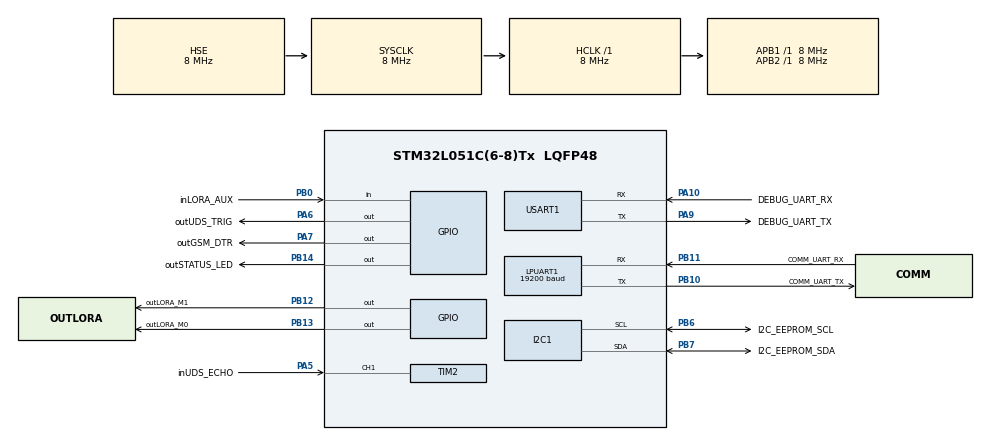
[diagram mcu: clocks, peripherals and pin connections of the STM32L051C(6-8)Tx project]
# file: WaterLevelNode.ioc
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ADC.ClockPrescaler=ADC_CLOCK_SYNC_PCLK_DIV4
ADC.SamplingTime=ADC_SAMPLETIME_7CYCLES_5
I2C1.I2C_Fall_Time=10
I2C1.I2C_Rise_Time=10
I2C1.Timing=0x2000090E
LPUART1.BaudRate=19200
LPUART1.WordLength=UART_WORDLENGTH_8B
Mcu.Family=STM32L0
Mcu.Name=STM32L051C(6-8)Tx
Mcu.Package=LQFP48
NVIC.LPUART1_IRQn=true\:0\:0\:false\:false\:true\:true\:true\:true
NVIC.RTC_IRQn=true\:0\:0\:false\:false\:true\:true\:true\:true
NVIC.TIM2_IRQn=true\:0\:0\:false\:false\:true\:true\:true\:true
NVIC.USART1_IRQn=true\:0\:0\:false\:false\:true\:true\:true\:true
PA10.GPIO_Label=DEBUG_UART_RX
PA10.Mode=Asynchronous
PA10.Signal=USART1_RX
PA13.Mode=Serial_Wire
PA13.Signal=SYS_SWDIO
PA14.Mode=Serial_Wire
PA14.Signal=SYS_SWCLK
PA5.GPIO_Label=inUDS_ECHO
PA5.Signal=S_TIM2_CH1
PA6.GPIO_Label=outUDS_TRIG
PA6.Signal=GPIO_Output
PA7.GPIO_Label=outGSM_DTR
PA7.PinState=GPIO_PIN_RESET
PA7.Signal=GPIO_Output
PA9.GPIO_Label=DEBUG_UART_TX
PA9.Mode=Asynchronous
PA9.Signal=USART1_TX
PB0.GPIO_Label=inLORA_AUX
PB0.Signal=GPIO_Input
PB10.GPIO_Label=COMM_UART_TX
PB10.GPIO_PuPd=GPIO_NOPULL
PB10.Mode=Asynchronous
PB10.Signal=LPUART1_TX
PB11.GPIO_Label=COMM_UART_RX
PB11.GPIO_PuPd=GPIO_NOPULL
PB11.Mode=Asynchronous
PB11.Signal=LPUART1_RX
PB12.GPIO_Label=outLORA_M1
PB12.Signal=GPIO_Output
PB13.GPIO_Label=outLORA_M0
PB13.Signal=GPIO_Output
PB14.GPIO_Label=outSTATUS_LED
PB14.Signal=GPIO_Output
PB6.GPIO_Label=I2C_EEPROM_SCL
PB6.GPIO_Pu=GPIO_PULLUP
PB6.Mode=I2C
PB6.Signal=I2C1_SCL
PB7.GPIO_Label=I2C_EEPROM_SDA
PB7.GPIO_Pu=GPIO_PULLUP
PB7.Mode=I2C
PB7.Signal=I2C1_SDA
PC14-OSC32_IN.Mode=LSE-External-Oscillator
PC14-OSC32_IN.Signal=RCC_OSC32_IN
PC15-OSC32_OUT.Mode=LSE-External-Oscillator
PC15-OSC32_OUT.Signal=RCC_OSC32_OUT
PH0-OSC_IN.Mode=HSE-External-Oscillator
PH0-OSC_IN.Signal=RCC_OSC_IN
PH1-OSC_OUT.Mode=HSE-External-Oscillator
PH1-OSC_OUT.Signal=RCC_OSC_OUT
ProjectManager.HeapSize=0x200
ProjectManager.StackSize=0x400
ProjectManager.TargetToolchain=CMake
RCC.AHBFreq_Value=8000000
RCC.APB1Freq_Value=8000000
RCC.APB1TimFreq_Value=8000000
RCC.APB2Freq_Value=8000000
RCC.APB2TimFreq_Value=8000000
RCC.HCLKFreq_Value=8000000
RCC.HSE_VALUE=8000000
RCC.HSI16_VALUE=16000000
RCC.HSI_VALUE=16000000
RCC.MSI_VALUE=2097000
RCC.PLLDIV=RCC_PLLDIV_3
RCC.PLLSourceVirtual=RCC_PLLSOURCE_HSE
RCC.RTCClockSelection=RCC_RTCCLKSOURCE_LSE
RCC.RTCClockSelectionVirtual=RCC_RTCCLKSOURCE_LSE
RCC.SYSCLKFreq_VALUE=8000000
RCC.SYSCLKSource=RCC_SYSCLKSOURCE_HSE
RCC.VCOOutputFreq_Value=24000000
RTC.WakeUpClock-WakeUp=RTC_WAKEUPCLOCK_CK_SPRE_16BITS
RTC.WakeUpCounter-WakeUp=10
SH.S_TIM2_CH1.0=TIM2_CH1,Input_Capture1_from_TI1
TIM2.Channel-Input_Capture1_from_TI1=TIM_CHANNEL_1
TIM2.ICPolarity_CH1=TIM_INPUTCHANNELPOLARITY_BOTHEDGE
TIM2.Prescaler=5-1
USART1.VirtualMode-Asynchronous=VM_ASYNC
VP_ADC_Vref_Input.Mode=IN-Vrefint
VP_RTC_VS_RTC_Activate.Mode=RTC_Enabled
VP_RTC_VS_RTC_WakeUp_intern.Mode=WakeUp
VP_TIM2_VS_ClockSourceINT.Mode=Internal
board=custom

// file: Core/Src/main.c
/* USER CODE BEGIN Header */
/**
  ******************************************************************************
  * @file           : main.c
  * @brief          : Main program body
  ******************************************************************************
  * @attention
  *
  * Copyright (c) 2024 STMicroelectronics.
  * All rights reserved.
  *
  * This software is licensed under terms that can be found in the LICENSE file
  * in the root directory of this software component.
  * If no LICENSE file comes with this software, it is provided AS-IS.
  *
  ******************************************************************************
  */
/* USER CODE END Header */
#include "main.h"
#include "adc.h"
#include "i2c.h"
#include "usart.h"
#include "rtc.h"
#include "tim.h"
#include "gpio.h"

/* USER CODE BEGIN Includes */
#include "main-app.h"
/* USER CODE END Includes */

void SystemClock_Config(void);

int main(void)
{

  /* MCU Configuration--------------------------------------------------------*/

  /* Reset of all peripherals, Initializes the Flash interface and the Systick. */
  HAL_Init();

  /* Configure the system clock */
  SystemClock_Config();

  /* USER CODE BEGIN SysInit */
  // __HAL_RCC_I2C1_CLK_ENABLE();
  // HAL_Delay(100);
  // __HAL_RCC_I2C1_FORCE_RESET();
  // HAL_Delay(100);
  // __HAL_RCC_I2C1_RELEASE_RESET();
  // HAL_Delay(100);
  #ifdef DEBUG
  HAL_DBGMCU_EnableDBGSleepMode();
  HAL_DBGMCU_EnableDBGStopMode();
  #endif
  /* USER CODE END SysInit */

  /* Initialize all configured peripherals */
  MX_GPIO_Init();
  MX_I2C1_Init();
  MX_LPUART1_UART_Init();
  MX_USART1_UART_Init();
  MX_TIM2_Init();
  MX_RTC_Init();
  MX_ADC_Init();
  /* USER CODE BEGIN 2 */
  MainAppInit();
  /* USER CODE END 2 */

  /* Infinite loop */
  while (1)
  {

    /* USER CODE BEGIN 3 */
    MainAppProcess();
  }
  /* USER CODE END 3 */
}

void SystemClock_Config(void)
{
  RCC_OscInitTypeDef RCC_OscInitStruct = {0};
  RCC_ClkInitTypeDef RCC_ClkInitStruct = {0};
  RCC_PeriphCLKInitTypeDef PeriphClkInit = {0};

  /** Configure the main internal regulator output voltage
  */
  __HAL_PWR_VOLTAGESCALING_CONFIG(PWR_REGULATOR_VOLTAGE_SCALE1);

  /** Configure LSE Drive Capability
  */
  HAL_PWR_EnableBkUpAccess();
  __HAL_RCC_LSEDRIVE_CONFIG(RCC_LSEDRIVE_LOW);

  /** Initializes the RCC Oscillators according to the specified parameters
  * in the RCC_OscInitTypeDef structure.
  */
  RCC_OscInitStruct.OscillatorType = RCC_OSCILLATORTYPE_HSE|RCC_OSCILLATORTYPE_LSE;
  RCC_OscInitStruct.HSEState = RCC_HSE_ON;
  RCC_OscInitStruct.LSEState = RCC_LSE_ON;
  RCC_OscInitStruct.PLL.PLLState = RCC_PLL_NONE;
  if (HAL_RCC_OscConfig(&RCC_OscInitStruct) != HAL_OK)
  {
    Error_Handler();
  }

  /** Initializes the CPU, AHB and APB buses clocks
  */
  RCC_ClkInitStruct.ClockType = RCC_CLOCKTYPE_HCLK|RCC_CLOCKTYPE_SYSCLK
                              |RCC_CLOCKTYPE_PCLK1|RCC_CLOCKTYPE_PCLK2;
  RCC_ClkInitStruct.SYSCLKSource = RCC_SYSCLKSOURCE_HSE;
  RCC_ClkInitStruct.AHBCLKDivider = RCC_SYSCLK_DIV1;
  RCC_ClkInitStruct.APB1CLKDivider = RCC_HCLK_DIV1;
  RCC_ClkInitStruct.APB2CLKDivider = RCC_HCLK_DIV1;

  if (HAL_RCC_ClockConfig(&RCC_ClkInitStruct, FLASH_LATENCY_0) != HAL_OK)
  {
    Error_Handler();
  }
  PeriphClkInit.PeriphClockSelection = RCC_PERIPHCLK_USART1|RCC_PERIPHCLK_LPUART1
                              |RCC_PERIPHCLK_I2C1|RCC_PERIPHCLK_RTC;
  PeriphClkInit.Usart1ClockSelection = RCC_USART1CLKSOURCE_PCLK2;
  PeriphClkInit.Lpuart1ClockSelection = RCC_LPUART1CLKSOURCE_PCLK1;
  PeriphClkInit.I2c1ClockSelection = RCC_I2C1CLKSOURCE_PCLK1;
  PeriphClkInit.RTCClockSelection = RCC_RTCCLKSOURCE_LSE;
  if (HAL_RCCEx_PeriphCLKConfig(&PeriphClkInit) != HAL_OK)
  {
    Error_Handler();
  }
}

void Error_Handler(void)
{
  __disable_irq();
  while (1)
  {
  }
}
